# CONTROLSS_INTXBAR_CONTROLSS_502D5000h register map
Vendor: Texas Instruments
Peripheral module from a debugger description file (folder AM261x).
Registers are 32-bit, read-write, reset 0x0 unless marked. A register's access mark holds for its fields unless they carry their own. Offsets are as the file gives them; lines under a group give offsets from that group; [hi:lo] are bit positions; {n}, {i} and the like mark numbered series; 'fields as' and 'values as' point back to an identical list; <NAME> marks a mode.

## CONTROLSS
{0x100+0x40*i} CONTROLSS_INTXBAR{i}_G0 (i=0..31) — INT XBAR {i} Input Select.
  [9:0] INTXBAR{i}_G0_SEL — EPWM INT interrupt to corresponding XBAR1:PWMx.INT is selected0:PWMx.INT is de-selected
{0x104+0x40*i} CONTROLSS_INTXBAR{i}_G1 (i=0..31) — INT XBAR {i} Input Select.
  [9:0] INTXBAR{i}_G1_SEL — EPWM TZINT interrupt to corresponding XBAR1:PWMx.TZINT is selected0:PWMx.TZINT is de-selected
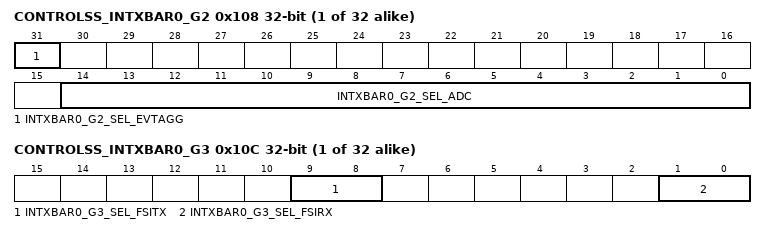
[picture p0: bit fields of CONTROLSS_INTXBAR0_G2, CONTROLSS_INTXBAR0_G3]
{0x108+0x40*i} CONTROLSS_INTXBAR{i}_G2 (i=0..31) — INT XBAR {i} Input Select.
  [31] INTXBAR{i}_G2_SEL_EVTAGG — Corresponding INT XBAR G2 Input Select31:ASC_AGG0.INT
  [14:0] INTXBAR{i}_G2_SEL_ADC — Corresponding INT XBAR G2 Input Select0:ADC0.INT11:ADC0.INT22:ADC0.INT33:ADC0.INT44:ADC0.EVTINT5:ADC1.INT16:ADC1.INT27:ADC1.INT38:ADC1.INT49:ADC1.EVTINT10:ADC2.INT111:ADC2.INT212:ADC2.INT313:ADC2.INT414:ADC2.EVTINT
{0x10C+0x40*i} CONTROLSS_INTXBAR{i}_G3 (i=0..31) — INT XBAR {i} Input Select.
  [9:8] INTXBAR{i}_G3_SEL_FSITX — Corresponding INT XBAR G3 Input Select8:FSITX0.INT1N9:FSITX0.INT2N
  [1:0] INTXBAR{i}_G3_SEL_FSIRX — Corresponding INT XBAR G3 Input Select0:FSIRX0.INT1N1:FSIRX0.INT2N
{0x110+0x40*i} CONTROLSS_INTXBAR{i}_G4 (i=0..31) — INT XBAR {i} Input Select.
  [9:0] INTXBAR{i}_G4_SEL — Corresponding INT XBAR G4 Input Select0:SD0.ERR1:SD0.FILT1.DRINT2:SD0.FILT2.DRINT3:SD0.FILT3.DRINT4:SD0.FILT4.DRINT5:SD1.ERR6:SD1.FILT1.DRINT7:SD1.FILT2.DRINT8:SD1.FILT3.DRINT9:SD1.FILT4.DRINT
{0x114+0x40*i} CONTROLSS_INTXBAR{i}_G5 (i=0..31) — INT XBAR {i} Input Select.
  [7:0] INTXBAR{i}_G5_SEL — Corresponding INT XBAR G5 Input Select0:ECAP0.INT1:ECAP1.INT2:ECAP2.INT3:ECAP3.INT4:ECAP4.INT5:ECAP5.INT6:ECAP6.INT7:ECAP7.INT
{0x118+0x40*i} CONTROLSS_INTXBAR{i}_G6 (i=0..31) — INT XBAR {i} Input Select.
  [1:0] INTXBAR{i}_G6_SEL — Corresponding INT XBAR G6 Input Select0:EQEP0.INT1:EQEP1.INT
{0x11C+0x40*i} CONTROLSS_INTXBAR{i}_G7 (i=0..11) — INT XBAR {i} Input Select.
  [17:0] INTXBAR{i}_G7_SEL — Corresponding INT XBAR G8 Input Select0:CMP12SSA0.CTRIPL1:CMP12SSA0.CTRIPH2:CMP12SSA1.CTRIPL3:CMP12SSA1.CTRIPH4:CMP12SSA2.CTRIPL5:CMP12SSA2.CTRIPH6:CMP12SSA3.CTRIPL7:CMP12SSA3.CTRIPH8:CMP12SSA4.CTRIPL9:CMP12SSA4.CTRIPH10:CMP12SSA5.CTRIPL11:CMP12SSA5.CTRIPH12:CMP12SSA6.CTRIPL13:CMP12SSA6.CTRIPH14:CMP12SSA7.CTRIPL15:CMP12SSA7.CTRIPH16:CMP12SSA8.CTRIPL17:CMP12SSA8.CTRIPH
{0x11C+0x40*i} CONTROLSS_INTXBAR{i}_G7 (i=12..31) — INT XBAR {i} Input Select.
  [17:0] INTXBAR{i}_G7_SEL — Corresponding INT XBAR G7 Input Select0:CMP12SSA0.CTRIPL1:CMP12SSA0.CTRIPH2:CMP12SSA1.CTRIPL3:CMP12SSA1.CTRIPH4:CMP12SSA2.CTRIPL5:CMP12SSA2.CTRIPH6:CMP12SSA3.CTRIPL7:CMP12SSA3.CTRIPH8:CMP12SSA4.CTRIPL9:CMP12SSA4.CTRIPH10:CMP12SSA5.CTRIPL11:CMP12SSA5.CTRIPH12:CMP12SSA6.CTRIPL13:CMP12SSA6.CTRIPH14:CMP12SSA7.CTRIPL15:CMP12SSA7.CTRIPH16:CMP12SSA8.CTRIPL17:CMP12SSA8.CTRIPH
